# A31L12x register map
Vendor: VENDOR ABOV Semiconductor Co., Ltd.; Series: A31L12x; File version: 1.0
CPU: CM0+ r0p1, little endian, no MPU, no FPU, VTOR, 2 interrupt priority bits
Registers are 32-bit, read-write, reset 0x0 unless marked. A register's access mark holds for its fields unless they carry their own. Offsets are from the block's base; [hi:lo] are bit positions; {n}, {i} and the like mark numbered series; 'fields as' and 'values as' point back to an identical list.

## INTC — Interrupt Controller
Base 0x40001000
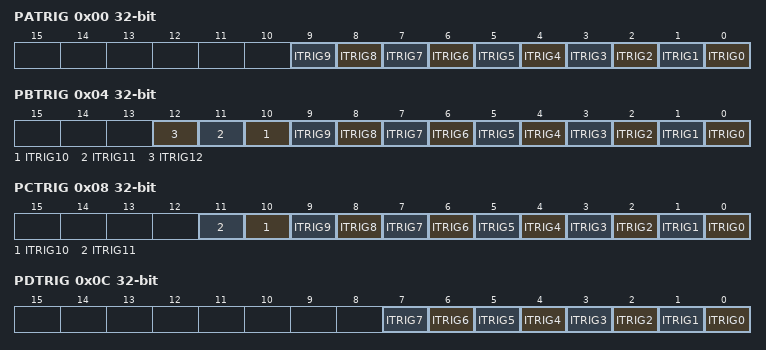
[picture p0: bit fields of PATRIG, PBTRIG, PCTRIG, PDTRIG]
0x00 PATRIG — Port A Interrupt Trigger Selection Register
  [all] fields
    0=Edge trigger interrupt; 1=Level trigger interrupt
  [n] ITRIG{n} (n=0..9) — Port A Interrupt Trigger Selection {n}
0x04 PBTRIG — Port B Interrupt Trigger Selection Register
  [all] fields
    0=Edge trigger interrupt; 1=Level trigger interrupt
  [n] ITRIG{n} (n=0..12) — Port B Interrupt Trigger Selection {n}
0x08 PCTRIG — Port C Interrupt Trigger Selection Register
  [all] fields
    0=Edge trigger interrupt; 1=Level trigger interrupt
  [n] ITRIG{n} (n=0..11) — Port C Interrupt Trigger Selection {n}
0x0C PDTRIG — Port D Interrupt Trigger Selection Register
  [all] fields
    0=Edge trigger interrupt; 1=Level trigger interrupt
  [n] ITRIG{n} (n=0..7) — Port D Interrupt Trigger Selection {n}
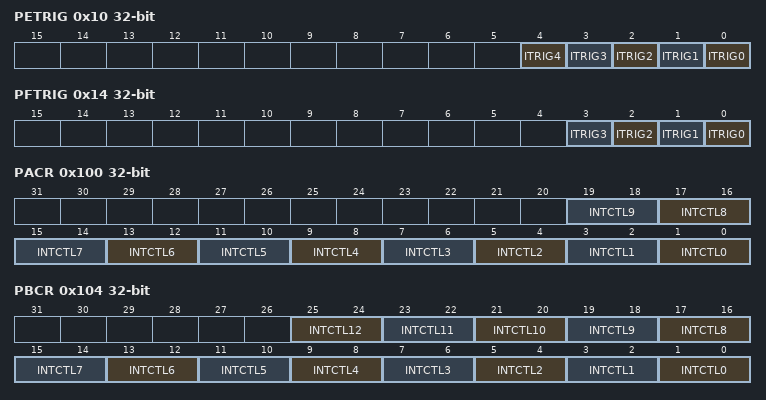
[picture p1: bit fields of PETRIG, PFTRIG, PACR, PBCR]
0x10 PETRIG — Port E Interrupt Trigger Selection Register
  [all] fields
    0=Edge trigger interrupt; 1=Level trigger interrupt
  [n] ITRIG{n} (n=0..4) — Port E Interrupt Trigger Selection {n}
0x14 PFTRIG — Port F Interrupt Trigger Selection Register
  [all] fields
    0=Edge trigger interrupt; 1=Level trigger interrupt
  [n] ITRIG{n} (n=0..3) — Port F Interrupt Trigger Selection {n}
0x100 PACR — Port A Interrupt Control Register
  [all] fields
    0=Disable external interrupt; 1=FallingEdgeLowLevel (Interrupt on falling edge or on low level); 2=RisingEdgeHighLevel (Interrupt on rising edge or on high level); 3=BothEdgeNoLevel (Interrupt on both falling and rising edge, No level interrupt)
  [2n+1:2n] INTCTL{n} (n=0..9) — Port A Interrupt Control {n}
0x104 PBCR — Port B Interrupt Control Register
  [all] fields
    values as the fields of PACR
  [2n+1:2n] INTCTL{n} (n=0..12) — Port B Interrupt Control {n}
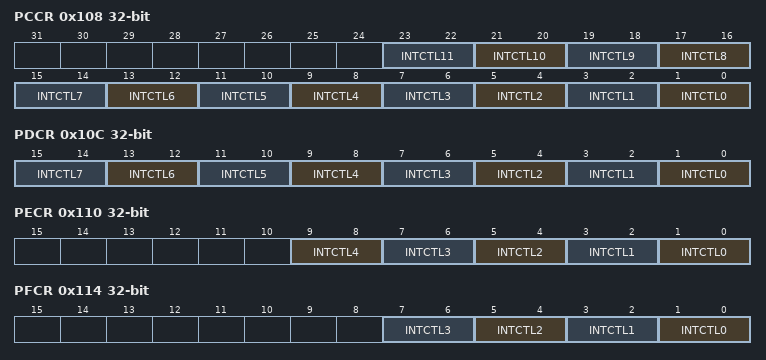
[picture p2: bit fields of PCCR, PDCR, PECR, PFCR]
0x108 PCCR — Port C Interrupt Control Register
  [all] fields
    values as the fields of PACR
  [2n+1:2n] INTCTL{n} (n=0..11) — Port C Interrupt Control {n}
0x10C PDCR — Port D Interrupt Control Register
  [all] fields
    values as the fields of PACR
  [2n+1:2n] INTCTL{n} (n=0..7) — Port D Interrupt Control {n}
0x110 PECR — Port E Interrupt Control Register
  [all] fields
    values as the fields of PACR
  [2n+1:2n] INTCTL{n} (n=0..4) — Port E Interrupt Control {n}
0x114 PFCR — Port F Interrupt Control Register
  [all] fields
    values as the fields of PACR
  [2n+1:2n] INTCTL{n} (n=0..3) — Port F Interrupt Control {n}
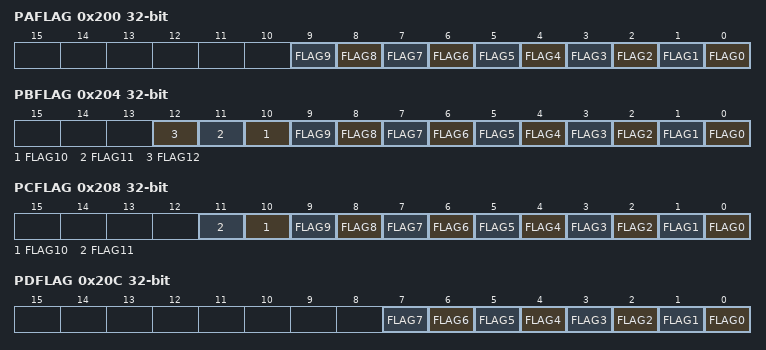
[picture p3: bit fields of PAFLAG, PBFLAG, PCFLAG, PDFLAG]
0x200 PAFLAG — Port A Interrupt Flag Register
  [all] fields
    0=No request occurred; 1=Request occurred
  [n] FLAG{n} (n=0..9) — Port A Interrupt Flag {n}
0x204 PBFLAG — Port B Interrupt Flag Register
  [all] fields
    0=No request occurred; 1=Request occurred
  [n] FLAG{n} (n=0..12) — Port B Interrupt Flag {n}
0x208 PCFLAG — Port C Interrupt Flag Register
  [all] fields
    0=No request occurred; 1=Request occurred
  [n] FLAG{n} (n=0..11) — Port C Interrupt Flag {n}
0x20C PDFLAG — Port D Interrupt Flag Register
  [all] fields
    0=No request occurred; 1=Request occurred
  [n] FLAG{n} (n=0..7) — Port D Interrupt Flag {n}
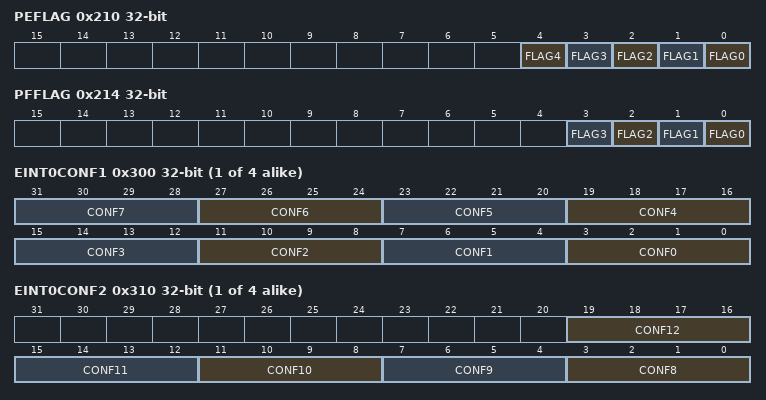
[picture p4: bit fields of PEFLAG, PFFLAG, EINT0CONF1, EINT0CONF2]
0x210 PEFLAG — Port E Interrupt Flag Register
  [all] fields
    0=No request occurred; 1=Request occurred
  [n] FLAG{n} (n=0..4) — Port E Interrupt Flag {n}
0x214 PFFLAG — Port F Interrupt Flag Register
  [all] fields
    0=No request occurred; 1=Request occurred
  [n] FLAG{n} (n=0..3) — Port F Interrupt Flag {n}
{0x300+4i} EINT{i}CONF1 (i=0..3) — External Interrupt {i} Configuration Register 1
  [all] fields
    0=PA (Select PA.); 1=PB (Select PB.); 2=PC (Select PC.); 3=PD (Select PD.); 4=PE (Select PE.); 5=PF (Select PF.)
  [4n+3:4n] CONF{n} (n=0..7) — External Interrupt {i} Configuration {n}
{0x310+4i} EINT{i}CONF2 (i=0..3) — External Interrupt {i} Configuration Register 2
  [all] fields
    values as the fields of EINT0CONF1
  [4n-29:4n-32] CONF{n} (n=8..12) — External Interrupt {i} Configuration {n}
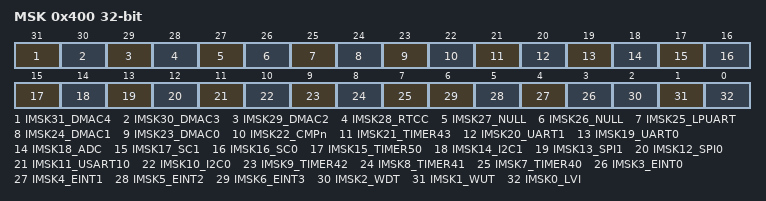
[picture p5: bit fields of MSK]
0x400 MSK — Interrupt Source Mask Register
  [all] fields
    0=Mask Interrupt Source; 1=Unmask Interrupt Source
  [31] IMSK31_DMAC4 — Interrupt Source Mask 31 (DMAC4)
  [30] IMSK30_DMAC3 — Interrupt Source Mask 30 (DMAC3)
  [29] IMSK29_DMAC2 — Interrupt Source Mask 29 (DMAC2)
  [28] IMSK28_RTCC — Interrupt Source Mask 28 (RTCC)
  [27] IMSK27_NULL — Interrupt Source Mask 27 (RSVD)
  [26] IMSK26_NULL — Interrupt Source Mask 26 (RSVD)
  [25] IMSK25_LPUART — Interrupt Source Mask 25 (LPUART)
  [24] IMSK24_DMAC1 — Interrupt Source Mask 24 (DMAC1)
  [23] IMSK23_DMAC0 — Interrupt Source Mask 23 (DMAC0)
  [22] IMSK22_CMPn — Interrupt Source Mask 22 (CMP)
  [21] IMSK21_TIMER43 — Interrupt Source Mask 21 (TIMER43)
  [20] IMSK20_UART1 — Interrupt Source Mask 20 (UART1)
  [19] IMSK19_UART0 — Interrupt Source Mask 19 (UART0)
  [18] IMSK18_ADC — Interrupt Source Mask 18 (ADC)
  [17] IMSK17_SC1 — Interrupt Source Mask 17 (SC1)
  [16] IMSK16_SC0 — Interrupt Source Mask 16 (SC0)
  [15] IMSK15_TIMER50 — Interrupt Source Mask 15 (TIMER50)
  [14] IMSK14_I2C1 — Interrupt Source Mask 14 (I2C1)
  [13] IMSK13_SPI1 — Interrupt Source Mask 13 (SPI1)
  [12] IMSK12_SPI0 — Interrupt Source Mask 12 (SPI0)
  [11] IMSK11_USART10 — Interrupt Source Mask 11 (USART10)
  [10] IMSK10_I2C0 — Interrupt Source Mask 10 (I2C0)
  [9] IMSK9_TIMER42 — Interrupt Source Mask 9 (TIMER42)
  [8] IMSK8_TIMER41 — Interrupt Source Mask 8 (TIMER41)
  [7] IMSK7_TIMER40 — Interrupt Source Mask 7 (TIMER40)
  [n] IMSK{n}_EINT{n-3} (n=3..6) — Interrupt Source Mask {n} (EINT{n-3})
  [2] IMSK2_WDT — Interrupt Source Mask 2 (WDT)
  [1] IMSK1_WUT — Interrupt Source Mask 1 (WUT)
  [0] IMSK0_LVI — Interrupt Source Mask 0 (LVI)

## Notices in the file
Copyright (C) 2012 ARM Limited. All rights reserved.
Purpose: System Viewer Description (SVD) Example (Schema Version 1.1)
This is a description of a none-existent and incomplete device
for demonstration purposes only.
Redistribution and use in source and binary forms, with or without
modification, are permitted provided that the following conditions are met:
- Redistributions of source code must retain the above copyright
notice, this list of conditions and the following disclaimer.
- Redistributions in binary form must reproduce the above copyright
notice, this list of conditions and the following disclaimer in the
documentation and/or other materials provided with the distribution.
- Neither the name of ARM nor the names of its contributors may be used
to endorse or promote products derived from this software without
specific prior written permission.
THIS SOFTWARE IS PROVIDED BY THE COPYRIGHT HOLDERS AND CONTRIBUTORS "AS IS"
AND ANY EXPRESS OR IMPLIED WARRANTIES, INCLUDING, BUT NOT LIMITED TO, THE
IMPLIED WARRANTIES OF MERCHANTABILITY AND FITNESS FOR A PARTICULAR PURPOSE
ARE DISCLAIMED. IN NO EVENT SHALL COPYRIGHT HOLDERS AND CONTRIBUTORS BE
LIABLE FOR ANY DIRECT, INDIRECT, INCIDENTAL, SPECIAL, EXEMPLARY, OR
CONSEQUENTIAL DAMAGES (INCLUDING, BUT NOT LIMITED TO, PROCUREMENT OF
SUBSTITUTE GOODS OR SERVICES; LOSS OF USE, DATA, OR PROFITS; OR BUSINESS
INTERRUPTION) HOWEVER CAUSED AND ON ANY THEORY OF LIABILITY, WHETHER IN
CONTRACT, STRICT LIABILITY, OR TORT (INCLUDING NEGLIGENCE OR OTHERWISE)
ARISING IN ANY WAY OUT OF THE USE OF THIS SOFTWARE, EVEN IF ADVISED OF THE
POSSIBILITY OF SUCH DAMAGE.
